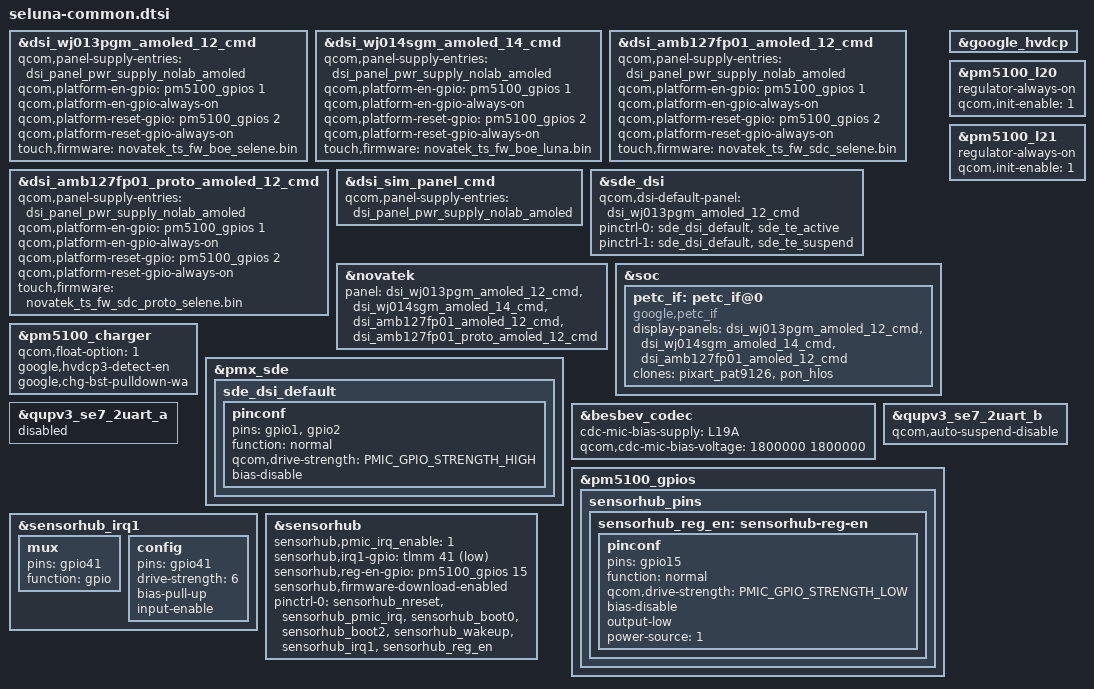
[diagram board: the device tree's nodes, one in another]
// SPDX-License-Identifier: GPL-2.0
#include <dt-bindings/gpio/gpio.h>
#include <dt-bindings/input/input.h>
#include <dt-bindings/pinctrl/qcom,pmic-gpio.h>

#include "../google-dts-base/sw5100-modem.dtsi"
#include "../google-dts-base/sw5100-common-memory.dtsi"
#include "../google-dts-base/sw5100-nanohub.dtsi"
#include "../google-dts-base/sw5100-sim-panel-cmd.dtsi"

#include "seluna-nfc.dtsi"
#include "selene-boe-display.dtsi"
#include "selene-sdc-display.dtsi"
#include "luna-boe-display.dtsi"
#include "seluna-bt.dtsi"
#include "seluna-uwb.dtsi"
#include "seluna-touch.dtsi"
#include "seluna-sdhc.dtsi"

&dsi_wj013pgm_amoled_12_cmd {
	qcom,panel-supply-entries = <&dsi_panel_pwr_supply_nolab_amoled>;
	qcom,platform-en-gpio = <&pm5100_gpios 1 0>;
	qcom,platform-en-gpio-always-on;
	qcom,platform-reset-gpio = <&pm5100_gpios 2 0>;
	qcom,platform-reset-gpio-always-on;
	touch,firmware = "novatek_ts_fw_boe_selene.bin";
};

&dsi_wj014sgm_amoled_14_cmd {
	qcom,panel-supply-entries = <&dsi_panel_pwr_supply_nolab_amoled>;
	qcom,platform-en-gpio = <&pm5100_gpios 1 0>;
	qcom,platform-en-gpio-always-on;
	qcom,platform-reset-gpio = <&pm5100_gpios 2 0>;
	qcom,platform-reset-gpio-always-on;
	touch,firmware = "novatek_ts_fw_boe_luna.bin";
};

&dsi_amb127fp01_amoled_12_cmd {
	qcom,panel-supply-entries = <&dsi_panel_pwr_supply_nolab_amoled>;
	qcom,platform-en-gpio = <&pm5100_gpios 1 0>;
	qcom,platform-en-gpio-always-on;
	qcom,platform-reset-gpio = <&pm5100_gpios 2 0>;
	qcom,platform-reset-gpio-always-on;
	touch,firmware = "novatek_ts_fw_sdc_selene.bin";
};

&dsi_amb127fp01_proto_amoled_12_cmd {
	qcom,panel-supply-entries = <&dsi_panel_pwr_supply_nolab_amoled>;
	qcom,platform-en-gpio = <&pm5100_gpios 1 0>;
	qcom,platform-en-gpio-always-on;
	qcom,platform-reset-gpio = <&pm5100_gpios 2 0>;
	qcom,platform-reset-gpio-always-on;
	touch,firmware = "novatek_ts_fw_sdc_proto_selene.bin";
};

&dsi_sim_panel_cmd {
    qcom,panel-supply-entries = <&dsi_panel_pwr_supply_nolab_amoled>;
};

&sde_dsi {
	qcom,dsi-default-panel = <&dsi_wj013pgm_amoled_12_cmd>;
};

&novatek {
	panel = <&dsi_wj013pgm_amoled_12_cmd
		&dsi_wj014sgm_amoled_14_cmd
		&dsi_amb127fp01_amoled_12_cmd
		&dsi_amb127fp01_proto_amoled_12_cmd>;
};

&soc {
	petc_if: petc_if@0 {
		compatible = "google,petc_if";
		display-panels = <&dsi_wj013pgm_amoled_12_cmd
			&dsi_wj014sgm_amoled_14_cmd
			&dsi_amb127fp01_amoled_12_cmd>;
		clones = <&pixart_pat9126 &pon_hlos>;
	};
};

&pm5100_charger {
	/* DCP mode for float chargers */
	qcom,float-option = <1>;

	/* Enable HVDCP3 (QC3) charger detection */
	google,hvdcp3-detect-en;

	/* Workaround: Use pulldown on CHG_BST to avoid Vreg settle timeout. */
	google,chg-bst-pulldown-wa;
};

&google_hvdcp {
	status = "okay";
};

&pm5100_l20 {
	regulator-always-on;
	qcom,init-enable = <1>;
};

&pm5100_l21 {
	regulator-always-on;
	qcom,init-enable = <1>;
};

&pmx_sde {
	sde_dsi_default: sde_dsi_default {
		pinconf {
			pins = "gpio1", "gpio2";
			function = "normal";
			qcom,drive-strength = <PMIC_GPIO_STRENGTH_HIGH>;
			bias-disable;
		};
	};
};

&sde_dsi {
	pinctrl-0 = <&sde_dsi_default &sde_te_active>;
	pinctrl-1 = <&sde_dsi_default &sde_te_suspend>;
};

&besbev_codec {
	cdc-mic-bias-supply = <&L19A>;
	qcom,cdc-mic-bias-voltage = <1800000 1800000>;
};

&qupv3_se7_2uart_a {
	status = "disabled";
};

&qupv3_se7_2uart_b {
	qcom,auto-suspend-disable;
	status = "ok";
};

&pm5100_gpios {
	sensorhub_pins {
		sensorhub_reg_en: sensorhub-reg-en {
			pinconf {
				pins = "gpio15";
				function = "normal";
				qcom,drive-strength = <PMIC_GPIO_STRENGTH_LOW>;
				bias-disable;
				output-low;
				power-source = <1>;
			};
		};
	};
};

&sensorhub_irq1 {
	mux {
		pins = "gpio41";
		function = "gpio";
	};
	config {
		pins = "gpio41";
		drive-strength = <6>;
		bias-pull-up;
		input-enable;
	};
};

&sensorhub {
	sensorhub,pmic_irq_enable = <1>;
	sensorhub,irq1-gpio = <&tlmm 41 GPIO_ACTIVE_LOW>;
	sensorhub,reg-en-gpio = <&pm5100_gpios 15 0>;
	sensorhub,firmware-download-enabled;

	pinctrl-0 = <&sensorhub_nreset &sensorhub_pmic_irq &sensorhub_boot0
	             &sensorhub_boot2 &sensorhub_wakeup &sensorhub_irq1
	             &sensorhub_reg_en>;
};
